AUTOSAR XML (schema 00049)
package /ARRoot
  sender receiver interface LedCmd_SRInterface
    data BOOL
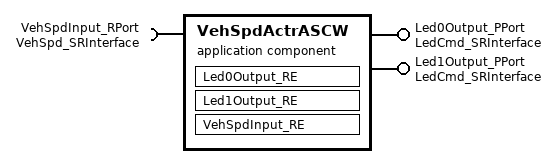
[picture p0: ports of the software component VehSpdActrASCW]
  application sw component type VehSpdActrASCW
    provide port Led0Output_PPort: provided-interface=LedCmd_SRInterface
    provide port Led1Output_PPort: provided-interface=LedCmd_SRInterface
    require port VehSpdInput_RPort: required-interface=VehSpd_SRInterface
    behavior VehSpdActr_IB
      runnable Led0Output_RE: variable-access=accessed-variable=Led0Output_PPort.BOOL.BOOL
      runnable Led1Output_RE: variable-access=accessed-variable=Led1Output_PPort.BOOL.BOOL
      runnable VehSpdInput_RE: variable-access=accessed-variable=VehSpdInput_RPort.UINT8.UINT8
  swc implementation VehSpdActr_SWComp
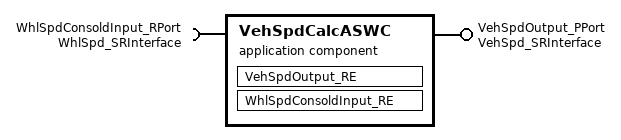
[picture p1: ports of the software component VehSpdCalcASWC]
  application sw component type VehSpdCalcASWC
    provide port VehSpdOutput_PPort: provided-interface=VehSpd_SRInterface
    require port WhlSpdConsoldInput_RPort: required-interface=WhlSpd_SRInterface
    behavior VehSpdCalc_IB
      runnable VehSpdOutput_RE: variable-access=accessed-variable=VehSpdOutput_PPort.UINT8.UINT8
      runnable WhlSpdConsoldInput_RE: variable-access=accessed-variable=WhlSpdConsoldInput_RPort.UINT8.UINT8
  swc implementation VehSpdCalc_SWComp: programming-language=C
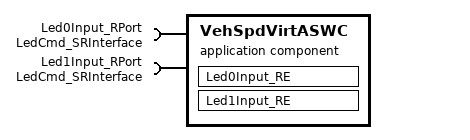
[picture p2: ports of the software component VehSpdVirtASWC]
  application sw component type VehSpdVirtASWC
    require port Led0Input_RPort: required-interface=LedCmd_SRInterface
    require port Led1Input_RPort: required-interface=LedCmd_SRInterface
    behavior VehSpdVirt_IB
      runnable Led0Input_RE: variable-access=accessed-variable=Led0Input_RPort.BOOL.BOOL
      runnable Led1Input_RE: variable-access=accessed-variable=Led1Input_RPort.BOOL.BOOL
      runnable Led1Input_RE: variable-access=accessed-variable=Led1Input_RPort.UINT8.UINT8
  swc implementation VehSpdVirt_SWComp: programming-language=C
  sender receiver interface VehSpd_SRInterface
    data UINT8
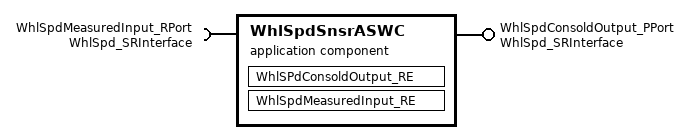
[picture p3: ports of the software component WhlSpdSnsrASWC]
  application sw component type WhlSpdSnsrASWC
    provide port WhlSpdConsoldOutput_PPort: provided-interface=WhlSpd_SRInterface
    require port WhlSpdMeasuredInput_RPort: required-interface=WhlSpd_SRInterface
    behavior WhlSpdSnsr_IB
      runnable WhlSPdConsoldOutput_RE: variable-access=accessed-variable=WhlSpdConsoldOutput_PPort.UINT8.UINT8
      runnable WhlSpdMeasuredInput_RE: variable-access=accessed-variable=WhlSpdMeasuredInput_RPort.UINT8.UINT8
  swc implementation WhlSpdSnsr_SWComp: programming-language=C
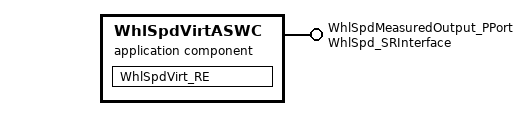
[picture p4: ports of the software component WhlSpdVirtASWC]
  application sw component type WhlSpdVirtASWC
    provide port WhlSpdMeasuredOutput_PPort: provided-interface=WhlSpd_SRInterface
    behavior WhlSpdVirt_IB
      runnable WhlSpdVirt_RE
  swc implementation WhlSpdVirt_SWComp: programming-language=C
  sender receiver interface WhlSpd_SRInterface
    data UINT8
